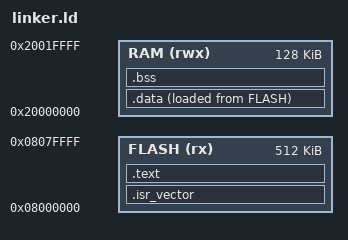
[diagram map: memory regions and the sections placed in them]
ENTRY(Reset_Handler)

MEMORY
{
  FLASH (rx)  : ORIGIN = 0x08000000, LENGTH = 512K
  RAM   (rwx) : ORIGIN = 0x20000000, LENGTH = 128K
}

_estack = ORIGIN(RAM) + LENGTH(RAM);

SECTIONS
{
  .isr_vector :
  {
    KEEP(*(.isr_vector))
  } > FLASH

  .text :
  {
    *(.text*)
    *(.rodata*)
  } > FLASH

  .data :
  {
    _sidata = LOADADDR(.data);
    _sdata = .;
    *(.data*)
    _edata = .;
  } > RAM AT > FLASH

  .bss (NOLOAD) :
  {
    _sbss = .;
    *(.bss*)
    *(COMMON)
    _ebss = .;
  } > RAM
}
